# STM32H523 register map
File version: 1.3
CPU: CM33 r0p0, little endian, MPU, FPU, 4 interrupt priority bits
Registers are 32-bit, read-write, reset 0x0 unless marked. A register's access mark holds for its fields unless they carry their own. Offsets are from the block's base; [hi:lo] are bit positions; {n}, {i} and the like mark numbered series; 'fields as' and 'values as' point back to an identical list.

## RCC — RCC address block description
Base 0x44020C00
Same registers: RCC_S 0x54020C00
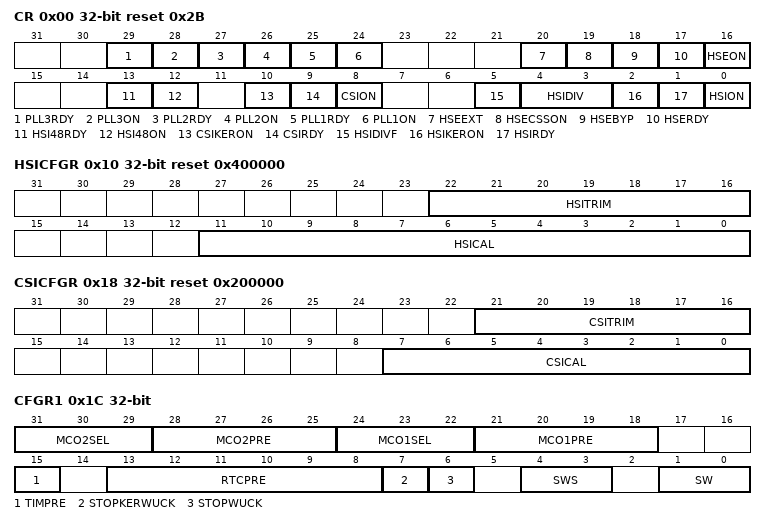
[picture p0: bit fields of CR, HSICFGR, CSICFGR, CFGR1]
0x00 CR reset 0x2B — RCC clock control register
  [29] PLL3RDY ro — PLL3 clock ready flag
    0=NotReady (Clock not ready); 1=Ready (Clock ready)
  [28] PLL3ON — PLL3 enable
    0=Off (Clock Off); 1=On (Clock On)
  [27] PLL2RDY ro — PLL2 clock ready flag
    0=NotReady (Clock not ready); 1=Ready (Clock ready)
  [26] PLL2ON — PLL2 enable
    0=Off (Clock Off); 1=On (Clock On)
  [25] PLL1RDY ro — PLL1 clock ready flag
    0=NotReady (Clock not ready); 1=Ready (Clock ready)
  [24] PLL1ON — PLL1 enable
    0=Off (Clock Off); 1=On (Clock On)
  [20] HSEEXT — external high speed clock type in Bypass mode
    0=Analog (HSE in analog mode); 1=Digital (HSE in digital mode)
  [19] HSECSSON — HSE clock security system enable
    0=Off (Clock Off); 1=On (Clock On)
  [18] HSEBYP — HSE clock bypass
    0=NotBypassed (HSE crystal oscillator not bypassed); 1=Bypassed (HSE crystal oscillator bypassed with external clock)
  [17] HSERDY ro — HSE clock ready flag
    0=NotReady (Clock not ready); 1=Ready (Clock ready)
  [16] HSEON — HSE clock enable
    0=Off (Clock Off); 1=On (Clock On)
  [13] HSI48RDY ro — HSI48 clock ready flag
    0=NotReady (Clock not ready); 1=Ready (Clock ready)
  [12] HSI48ON — HSI48 clock enable
    0=Off (Clock Off); 1=On (Clock On)
  [10] CSIKERON — CSI clock enable in Stop mode
    0=Off (Clock Off); 1=On (Clock On)
  [9] CSIRDY ro — CSI clock ready flag
    0=NotReady (Clock not ready); 1=Ready (Clock ready)
  [8] CSION — CSI clock enable
    0=Off (Clock Off); 1=On (Clock On)
  [5] HSIDIVF ro — HSI divider flag
    0=NotPropagated (New HSIDIV ratio has not yet propagated to hsi_ck); 1=Propagated (HSIDIV ratio has propagated to hsi_ck)
  [4:3] HSIDIV — HSI clock divider
    0=Div1 (No division); 1=Div2 (Division by 2); 2=Div4 (Division by 4); 3=Div8 (Division by 8)
  [2] HSIKERON — HSI clock enable in Stop mode
    0=Off (Clock Off); 1=On (Clock On)
  [1] HSIRDY ro — HSI clock ready flag
    0=NotReady (Clock not ready); 1=Ready (Clock ready)
  [0] HSION — HSI clock enable
    0=Off (Clock Off); 1=On (Clock On)
0x10 HSICFGR reset 0x400000 (reset mask 0xFFFFF000) — RCC HSI calibration register
  [22:16] HSITRIM — HSI clock trimming
  [11:0] HSICAL ro — HSI clock calibration
0x14 CRRCR ro (reset mask 0xFFFFF000) — RCC clock recovery RC register
  [9:0] HSI48CAL — Internal RC 48 MHz clock calibration
0x18 CSICFGR reset 0x200000 (reset mask 0xFFFFF000) — RCC CSI calibration register
  [21:16] CSITRIM — CSI clock trimming
  [7:0] CSICAL — CSI clock calibration
0x1C CFGR1 — RCC clock configuration register1
  [31:29] MCO2SEL — microcontroller clock output 2
    0=SYSCLK (System clock selected (sys_ck)); 1=PLL2_P (PLL2 oscillator clock selected (pll2_p_ck)); 2=HSE (HSE clock selected (hse_ck)); 3=PLL1_P (PLL1 clock selected (pll1_p_ck)); 4=CSI (CSI clock selected (csi_ck)); 5=LSI (LSI clock selected (lsi_ck))
  [28:25] MCO2PRE — MCO2 prescaler
  [24:22] MCO1SEL — Microcontroller clock output 1
    0=HSI (HSI clock selected (hsi_ck)); 1=LSE (LSE clock selected (lse_ck)); 2=HSE (HSE clock selected (hse_ck)); 3=PLL1_Q (PLL1 clock selected (pll1_q_ck)); 4=HSI48 (HSI48 clock selected (hsi48_ck))
  [21:18] MCO1PRE — MCO1 prescaler
  [15] TIMPRE — timers clocks prescaler selection
    0=DefaultX2 (Timer kernel clock equal to 2x pclk by default); 1=DefaultX4 (Timer kernel clock equal to 4x pclk by default)
  [13:8] RTCPRE — HSE division factor for RTC clock
  [7] STOPKERWUCK — kernel clock selection after a wakeup from system Stop
    0=HSI (HSI selected as wake up clock from system Stop); 1=CSI (CSI selected as wake up clock from system Stop)
  [6] STOPWUCK — system clock selection after a wakeup from system Stop
    values as STOPKERWUCK
  [4:3] SWS ro — system clock switch status
    0=HSI (HSI oscillator used as system clock); 1=CSI (CSI oscillator used as system clock); 2=HSE (HSE oscillator used as system clock); 3=PLL1 (PLL1 used as system clock)
  [1:0] SW — system clock and trace clock switch
    0=HSI (HSI selected as system clock); 1=CSI (CSI selected as system clock); 2=HSE (HSE selected as system clock); 3=PLL1 (PLL1 selected as system clock)
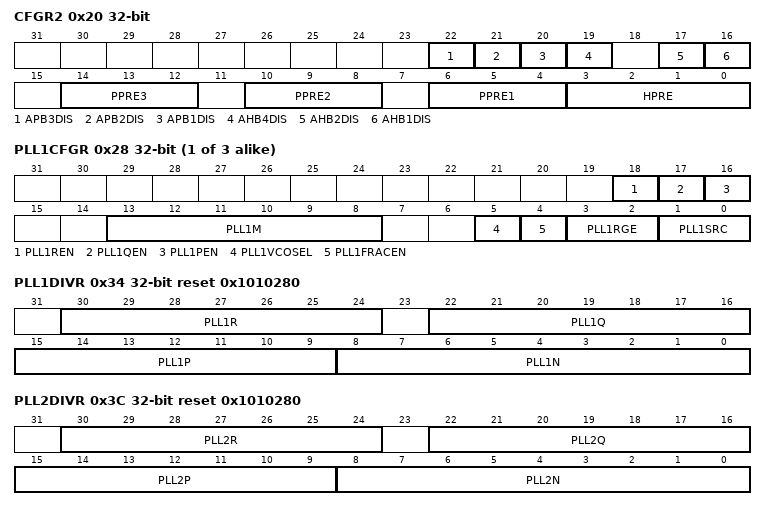
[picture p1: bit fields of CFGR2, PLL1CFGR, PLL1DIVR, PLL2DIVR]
0x20 CFGR2 — RCC CPU domain clock configuration register 2
  [22] APB3DIS — APB3 clock disable value.
    0=Enabled (The selected clock is enabled); 1=Disabled (The selected clock is disabled)
  [21] APB2DIS — APB2 clock disable value
    values as APB3DIS
  [20] APB1DIS — APB1 clock disable value
    values as APB3DIS
  [19] AHB4DIS — AHB4 clock disable
    values as APB3DIS
  [17] AHB2DIS — AHB2 clock disable
    values as APB3DIS
  [16] AHB1DIS — AHB1 clock disable
    values as APB3DIS
  [14:12] PPRE3 — APB low-speed prescaler (APB3)
    4=Div2 (HCLK divided by 2); 5=Div4 (HCLK divided by 4); 6=Div8 (HCLK divided by 8); 7=Div16 (HCLK divided by 16); other=Div1 (HCLK not divided)
  [10:8] PPRE2 — APB high-speed prescaler (APB2)
    values as PPRE3
  [6:4] PPRE1 — APB low-speed prescaler (APB1)
    values as PPRE3
  [3:0] HPRE — AHB prescaler
    8=Div2 (SYSCLK divided by 2); 9=Div4 (SYSCLK divided by 4); 10=Div8 (SYSCLK divided by 8); 11=Div16 (SYSCLK divided by 16); 12=Div64 (SYSCLK divided by 64); 13=Div128 (SYSCLK divided by 128); 14=Div256 (SYSCLK divided by 256); 15=Div512 (SYSCLK divided by 512); other=Div1 (SYSCLK not divided)
{0x24+4i} PLL{i}CFGR (i=1..3) — RCC PLL clock source selection register
  [18] PLL{i}REN — PLL{i} DIVR divider output enable
    0=Disabled (Clock output is disabled); 1=Enabled (Clock output is enabled)
  [17] PLL{i}QEN — PLL{i} DIVQ divider output enable
    values as PLL{i}REN
  [16] PLL{i}PEN — PLL{i} DIVP divider output enable
    values as PLL{i}REN
  [13:8] PLL{i}M — prescaler for PLL{i}
  [5] PLL{i}VCOSEL — PLL{i} VCO selection
    0=WideVCO (VCO frequency range 192 to 836 MHz); 1=MediumVCO (VCO frequency range 150 to 420 MHz)
  [4] PLL{i}FRACEN — PLL{i} fractional latch enable
    0=Reset latch to transfer FRACN to the Sigma-Delta modulator; 1=Set (Set latch to transfer FRACN to the Sigma-Delta modulator)
  [3:2] PLL{i}RGE — PLL{i} input frequency range
    0=Range1 (Frequency is between 1 and 2 MHz); 1=Range2 (Frequency is between 2 and 4 MHz); 2=Range4 (Frequency is between 4 and 8 MHz); 3=Range8 (Frequency is between 8 and 16 MHz)
  [1:0] PLL{i}SRC — PLL{i}M and PLLs clock source selection
    0=None (No clock sent to DIVMx dividers and PLLs); 1=HSI (HSI selected as PLL clock); 2=CSI (CSI selected as PLL clock); 3=HSE (HSE selected as PLL clock)
0x34 PLL1DIVR reset 0x1010280 — RCC PLL1 dividers register
  [30:24] PLL1R — PLL1 DIVR division factor
  [22:16] PLL1Q — PLL1 DIVQ division factor
  [15:9] PLL1P — PLL1 DIVP division factor
  [8:0] PLL1N range 3..511 — Multiplication factor for PLL1VCO
{0x30+8i} PLL{i}FRACR (i=1..3) — RCC PLL{i} fractional divider register
  [15:3] PLL{i}FRACN — fractional part of the multiplication factor for PLL{i} VCO
0x3C PLL2DIVR reset 0x1010280 — RCC PLL1 dividers register
  [30:24] PLL2R — PLL2 DIVR division factor
  [22:16] PLL2Q — PLL2 DIVQ division factor
  [15:9] PLL2P — PLL2 DIVP division factor
  [8:0] PLL2N range 3..511 — Multiplication factor for PLL2VCO
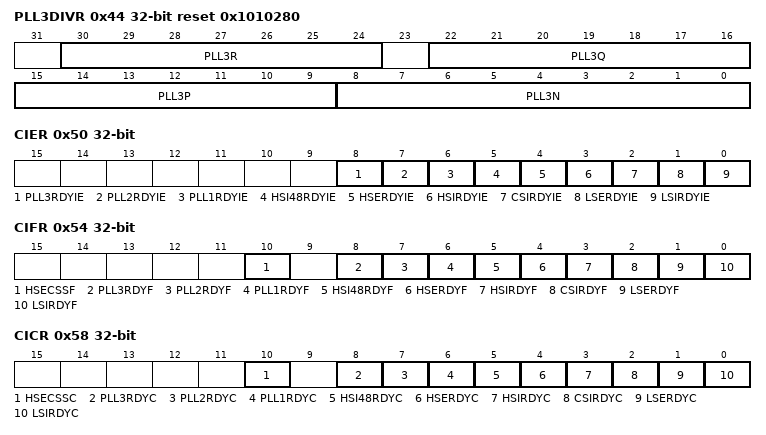
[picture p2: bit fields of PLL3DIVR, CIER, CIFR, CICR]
0x44 PLL3DIVR reset 0x1010280 — RCC PLL3 dividers register
  [30:24] PLL3R — PLL3 DIVR division factor
  [22:16] PLL3Q — PLL3 DIVQ division factor
  [15:9] PLL3P — PLL3 DIVP division factor
  [8:0] PLL3N range 3..511 — Multiplication factor for PLL3VCO
0x50 CIER — RCC clock source interrupt enable register
  [all] fields
    0=Disabled (Interrupt disabled); 1=Enabled (Interrupt enabled)
  [8] PLL3RDYIE — PLL3 ready interrupt enable
  [7] PLL2RDYIE — PLL2 ready interrupt enable
  [6] PLL1RDYIE — PLL1 ready interrupt enable
  [5] HSI48RDYIE — HSI48 ready interrupt enable
  [4] HSERDYIE — HSE ready interrupt enable
  [3] HSIRDYIE — HSI ready interrupt enable
  [2] CSIRDYIE — CSI ready interrupt enable
  [1] LSERDYIE — LSE ready interrupt enable
  [0] LSIRDYIE — LSI ready interrupt enable
0x54 CIFR ro — RCC clock source interrupt flag register
  [10] HSECSSF — HSE clock security system interrupt flag
    0=NoInterrupt (No clock security interrupt caused by HSE clock failure); 1=Interrupt (Clock security interrupt caused by HSE clock failure)
  [8] PLL3RDYF — PLL3 ready interrupt flag
    0=NotInterrupted (No clock ready interrupt); 1=Interrupted (Clock ready interrupt)
  [7] PLL2RDYF — PLL2 ready interrupt flag
    values as PLL3RDYF
  [6] PLL1RDYF — PLL1 ready interrupt flag
    values as PLL3RDYF
  [5] HSI48RDYF — HSI48 ready interrupt flag
    values as PLL3RDYF
  [4] HSERDYF — HSE ready interrupt flag
    values as PLL3RDYF
  [3] HSIRDYF — HSI ready interrupt flag
    values as PLL3RDYF
  [2] CSIRDYF — CSI ready interrupt flag
    values as PLL3RDYF
  [1] LSERDYF — LSE ready interrupt flag
    values as PLL3RDYF
  [0] LSIRDYF — LSI ready interrupt flag
    values as PLL3RDYF
0x58 CICR — RCC clock source interrupt clear register
  [all] fields
    1=Clear interrupt flag
  [10] HSECSSC — HSE clock security system interrupt clear
  [8] PLL3RDYC — PLL3 ready interrupt clear
  [7] PLL2RDYC — PLL2 ready interrupt clear
  [6] PLL1RDYC — PLL1 ready interrupt clear
  [5] HSI48RDYC — HSI48 ready interrupt clear
  [4] HSERDYC — HSE ready interrupt clear
  [3] HSIRDYC — HSI ready interrupt clear
  [2] CSIRDYC — HSI ready interrupt clear
  [1] LSERDYC — LSE ready interrupt clear
  [0] LSIRDYC — LSI ready interrupt clear
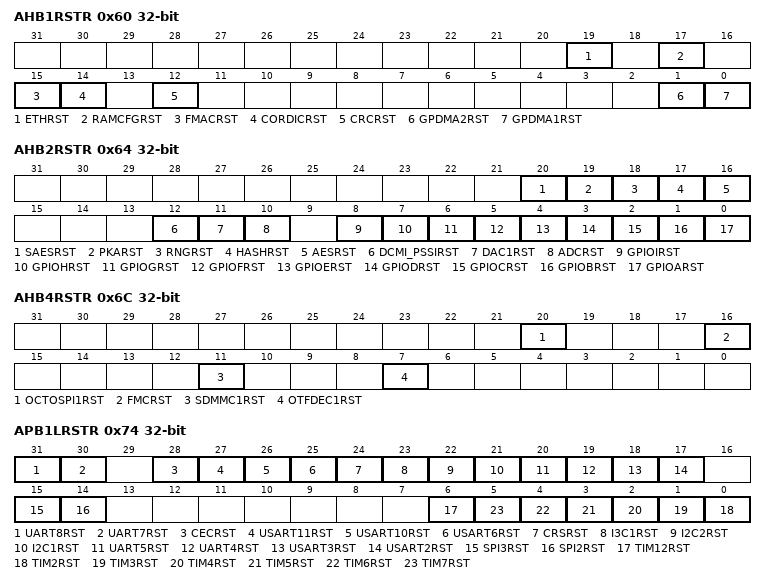
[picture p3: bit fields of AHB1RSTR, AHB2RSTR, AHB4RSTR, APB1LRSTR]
0x60 AHB1RSTR — RCC AHB1 reset register
  [all] fields
    1=Reset the selected module
  [19] ETHRST — ETHRST block reset
  [17] RAMCFGRST — RAMCFG block reset
  [15] FMACRST — FMAC block reset
  [14] CORDICRST — CORDIC block reset
  [12] CRCRST — CRC block reset Set and reset by software.
  [1] GPDMA2RST — GPDMA2 block reset
  [0] GPDMA1RST — GPDMA1 block reset
0x64 AHB2RSTR — RCC AHB2 peripheral reset register
  [all] fields
    1=Reset the selected module
  [20] SAESRST — SAES block reset
  [19] PKARST — PKA block reset
  [18] RNGRST — RNG block reset
  [17] HASHRST — HASH block reset
  [16] AESRST — AES block reset
  [12] DCMI_PSSIRST — digital camera interface block reset (DCMI or PSSI depending which interface is active)
  [11] DAC1RST — DAC block reset
  [10] ADCRST — ADC1 and 2 blocks reset
  [8] GPIOIRST — GPIOI block reset
  [7] GPIOHRST — GPIOH block reset
  [6] GPIOGRST — GPIOG block reset
  [5] GPIOFRST — GPIOF block reset
  [4] GPIOERST — GPIOE block reset
  [3] GPIODRST — GPIOD block reset
  [2] GPIOCRST — GPIOC block reset
  [1] GPIOBRST — GPIOB block reset
  [0] GPIOARST — GPIOA block reset
0x6C AHB4RSTR — RCC AHB4 peripheral reset register
  [all] fields
    1=Reset the selected module
  [20] OCTOSPI1RST — OCTOSPI1 block reset
  [16] FMCRST — FMC block reset
  [11] SDMMC1RST — SDMMC1 and SDMMC1 delay blocks reset
  [7] OTFDEC1RST — OTFDEC1 block reset
0x74 APB1LRSTR — RCC APB1 peripheral low reset register
  [all] fields
    1=Reset the selected module
  [31] UART8RST — UART8 block reset
  [30] UART7RST — UART7 block reset
  [28] CECRST — HDMI-CEC block reset
  [27] USART11RST — USART11 block reset
  [26] USART10RST — USART10 block reset
  [25] USART6RST — USART6 block reset
  [24] CRSRST — CRS block reset
  [23] I3C1RST — I3C1 block reset
  [22] I2C2RST — I2C2 block reset
  [21] I2C1RST — I2C1 block reset
  [20] UART5RST — UART5 block reset
  [19] UART4RST — UART4 block reset
  [18] USART3RST — USART3 block reset
  [17] USART2RST — USART2 block reset
  [15] SPI3RST — SPI3 block reset
  [14] SPI2RST — SPI2 block reset
  [6] TIM12RST — TIM12 block reset
  [n-2] TIM{n}RST (n=2..7) — TIM{n} block reset
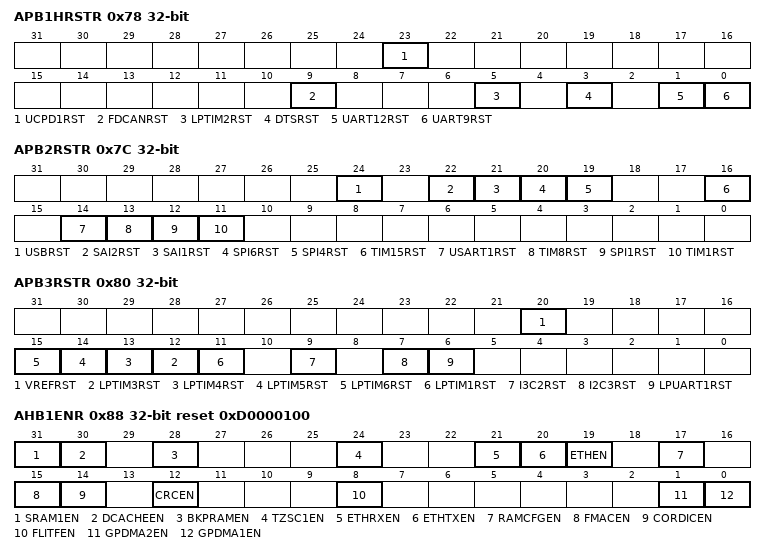
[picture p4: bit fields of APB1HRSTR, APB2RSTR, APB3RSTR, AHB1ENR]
0x78 APB1HRSTR — RCC APB1 peripheral high reset register
  [all] fields
    1=Reset the selected module
  [23] UCPD1RST — UCPD1 block reset
  [9] FDCANRST — FDCAN1 and FDCAN2 blocks reset
  [5] LPTIM2RST — LPTIM2 block reset
  [3] DTSRST — DTS block reset
  [1] UART12RST — UART12 block reset
  [0] UART9RST — UART9 block reset
0x7C APB2RSTR — RCC APB2 peripheral reset register
  [all] fields
    1=Reset the selected module
  [24] USBRST — USB block reset
  [22] SAI2RST — SAI2 block reset
  [21] SAI1RST — SAI1 block reset
  [20] SPI6RST — SPI6 block reset
  [19] SPI4RST — SPI4 block reset
  [16] TIM15RST — TIM15 block reset
  [14] USART1RST — USART1 block reset
  [13] TIM8RST — TIM8 block reset
  [12] SPI1RST — SPI1 block reset
  [11] TIM1RST — TIM1 block reset
0x80 APB3RSTR — RCC APB3 peripheral reset register
  [all] fields
    1=Reset the selected module
  [20] VREFRST — VREFBUF block reset
  [n+9] LPTIM{n}RST (n=3..6) — LPTIM{n} block reset
  [11] LPTIM1RST — LPTIM1 block reset
  [9] I3C2RST — I3C2 block reset
  [7] I2C3RST — I2C3 block reset
  [6] LPUART1RST — LPUART1 block reset
0x88 AHB1ENR reset 0xD0000100 — RCC AHB1 peripherals clock register
  [all] fields
    0=Disabled (The selected clock is disabled); 1=Enabled (The selected clock is enabled)
  [31] SRAM1EN — SRAM1 clock enable
  [30] DCACHEEN — DCACHE clock enable
  [28] BKPRAMEN — BKPRAM clock enable
  [24] TZSC1EN — TZSC1 clock enable
  [21] ETHRXEN — ETHRX clock enable
  [20] ETHTXEN — ETHTX clock enable
  [19] ETHEN — ETH clock enable
  [17] RAMCFGEN — RAMCFG clock enable
  [15] FMACEN — FMAC clock enable
  [14] CORDICEN — CORDIC clock enable
  [12] CRCEN — CRC clock enable
  [8] FLITFEN — Flash interface clock enable
  [1] GPDMA2EN — GPDMA2 clock enable
  [0] GPDMA1EN — GPDMA1 clock enable
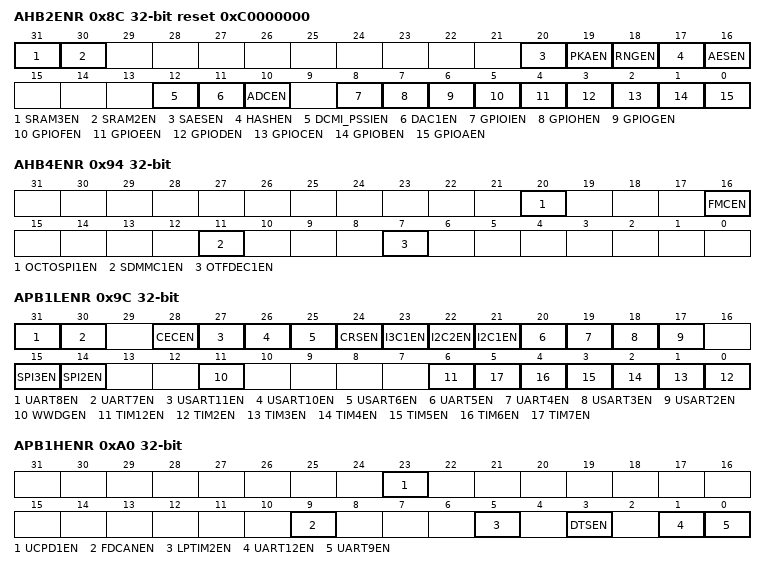
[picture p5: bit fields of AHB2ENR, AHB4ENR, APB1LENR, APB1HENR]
0x8C AHB2ENR reset 0xC0000000 — RCC AHB2 peripheral clock register
  [all] fields
    values as the fields of AHB1ENR
  [31] SRAM3EN — SRAM3 clock enable
  [30] SRAM2EN — SRAM2 clock enable
  [20] SAESEN — SAES clock enable
  [19] PKAEN — PKA clock enable
  [18] RNGEN — RNG clock enable
  [17] HASHEN — HASH clock enable
  [16] AESEN — AES clock enable
  [12] DCMI_PSSIEN — digital camera interface clock enable (DCMI or PSSI depending which interface is active)
  [11] DAC1EN — DAC clock enable
  [10] ADCEN — ADC1 and 2 peripherals clock enable
  [8] GPIOIEN — GPIOI clock enable
  [7] GPIOHEN — GPIOH clock enable
  [6] GPIOGEN — GPIOG clock enable
  [5] GPIOFEN — GPIOF clock enable
  [4] GPIOEEN — GPIOE clock enable
  [3] GPIODEN — GPIOD clock enable
  [2] GPIOCEN — GPIOC clock enable
  [1] GPIOBEN — GPIOB clock enable
  [0] GPIOAEN — GPIOA clock enable
0x94 AHB4ENR — RCC AHB4 peripheral clock register
  [all] fields
    values as the fields of AHB1ENR
  [20] OCTOSPI1EN — OCTOSPI1 clock enable
  [16] FMCEN — FMC clock enable
  [11] SDMMC1EN — SDMMC1 and SDMMC1 delay peripheral clock enable reset
  [7] OTFDEC1EN — OTFDEC1 clock enable
0x9C APB1LENR — RCC APB1 peripheral clock register
  [all] fields
    values as the fields of AHB1ENR
  [31] UART8EN — UART8 clock enable
  [30] UART7EN — UART7 clock enable
  [28] CECEN — HDMI-CEC clock enable
  [27] USART11EN — USART11 clock enable
  [26] USART10EN — USART10 clock enable
  [25] USART6EN — USART6 clock enable
  [24] CRSEN — CRS clock enable
  [23] I3C1EN — I3C1 clock enable
  [22] I2C2EN — I2C2 clock enable
  [21] I2C1EN — I2C1 clock enable
  [20] UART5EN — UART5 clock enable
  [19] UART4EN — UART4 clock enable
  [18] USART3EN — USART3 clock enable
  [17] USART2EN — USART2 clock enable
  [15] SPI3EN — SPI3 clock enable
  [14] SPI2EN — SPI2 clock enable
  [11] WWDGEN — WWDG clock enable
  [6] TIM12EN — TIM12 clock enable
  [n-2] TIM{n}EN (n=2..7) — TIM{n} clock enable
0xA0 APB1HENR — RCC APB1 peripheral clock register
  [all] fields
    values as the fields of AHB1ENR
  [23] UCPD1EN — UCPD1 clock enable
  [9] FDCANEN — FDCAN1 and FDCAN2 peripheral clock enable
  [5] LPTIM2EN — LPTIM2 clock enable
  [3] DTSEN — DTS clock enable
  [1] UART12EN — UART12 clock enable
  [0] UART9EN — UART9 clock enable
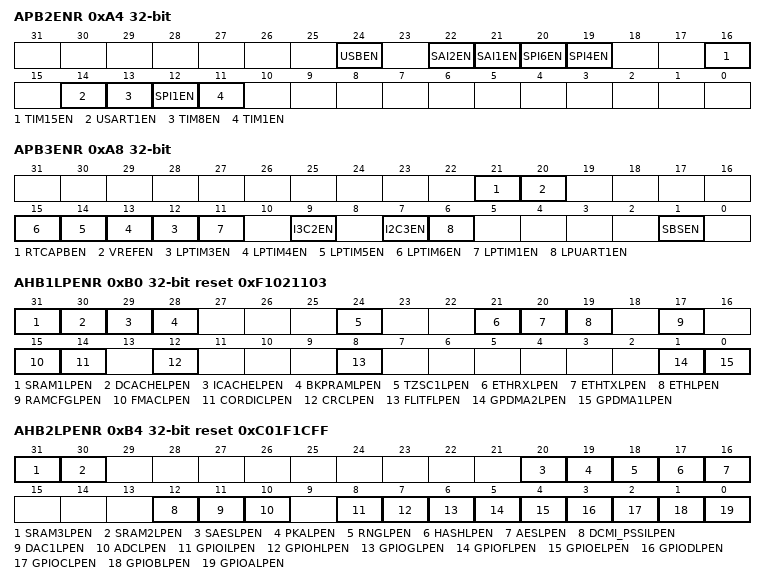
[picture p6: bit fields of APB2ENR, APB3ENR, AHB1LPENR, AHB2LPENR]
0xA4 APB2ENR — RCC APB2 peripheral clock register
  [all] fields
    values as the fields of AHB1ENR
  [24] USBEN — USB clock enable
  [22] SAI2EN — SAI2 clock enable
  [21] SAI1EN — SAI1 clock enable
  [20] SPI6EN — SPI6 clock enable
  [19] SPI4EN — SPI4 clock enable
  [16] TIM15EN — TIM15 clock enable
  [14] USART1EN — USART1 clock enable
  [13] TIM8EN — TIM8 clock enable
  [12] SPI1EN — SPI1 clock enable
  [11] TIM1EN — TIM1 clock enable
0xA8 APB3ENR — RCC APB3 peripheral clock register
  [all] fields
    values as the fields of AHB1ENR
  [21] RTCAPBEN — RTC APB interface clock enable
  [20] VREFEN — VREFBUF clock enable
  [n+9] LPTIM{n}EN (n=3..6) — LPTIM{n} clock enable
  [11] LPTIM1EN — LPTIM1 clock enable
  [9] I3C2EN — I3C2 clock enable
  [7] I2C3EN — I2C3 clock enable
  [6] LPUART1EN — LPUART1 clock enable
  [1] SBSEN — SBS clock enable
0xB0 AHB1LPENR reset 0xF1021103 — RCC AHB1 sleep clock register
  [all] fields
    0=Disabled (The selected clock is disabled during csleep mode); 1=Enabled (The selected clock is enabled during csleep mode)
  [31] SRAM1LPEN — SRAM1 clock enable during Sleep mode
  [30] DCACHELPEN — DCACHE clock enable during Sleep mode
  [29] ICACHELPEN — ICACHE clock enable during Sleep mode
  [28] BKPRAMLPEN — BKPRAM clock enable during Sleep mode
  [24] TZSC1LPEN — TZSC1 clock enable during Sleep mode
  [21] ETHRXLPEN — ETHRX clock enable during Sleep mode
  [20] ETHTXLPEN — ETHTX clock enable during Sleep mode
  [19] ETHLPEN — ETH clock enable during Sleep mode
  [17] RAMCFGLPEN — RAMCFG clock enable during Sleep mode
  [15] FMACLPEN — FMAC clock enable during Sleep mode
  [14] CORDICLPEN — CORDIC clock enable during Sleep mode
  [12] CRCLPEN — CRC clock enable during Sleep mode
  [8] FLITFLPEN — Flash interface (FLITF) clock enable during Sleep mode
  [1] GPDMA2LPEN — GPDMA2 clock enable during Sleep mode
  [0] GPDMA1LPEN — GPDMA1 clock enable during Sleep mode
0xB4 AHB2LPENR reset 0xC01F1CFF — RCC AHB2 sleep clock register
  [all] fields
    values as the fields of AHB1LPENR
  [31] SRAM3LPEN — SRAM3 clock enable during Sleep mode
  [30] SRAM2LPEN — SRAM2 clock enable during Sleep mode
  [20] SAESLPEN — SAES clock enable during Sleep mode
  [19] PKALPEN — PKA clock enable during Sleep mode
  [18] RNGLPEN — RNG clock enable during Sleep mode
  [17] HASHLPEN — HASH clock enable during Sleep mode
  [16] AESLPEN — AES clock enable during Sleep mode
  [12] DCMI_PSSILPEN — digital camera interface clock enable during Sleep mode (DCMI or PSSI depending which interface is active)
  [11] DAC1LPEN — DAC clock enable during Sleep mode
  [10] ADCLPEN — ADC1 and 2 peripherals clock enable during Sleep mode
  [8] GPIOILPEN — GPIOI clock enable during Sleep mode
  [7] GPIOHLPEN — GPIOH clock enable during Sleep mode
  [6] GPIOGLPEN — GPIOG clock enable during Sleep mode
  [5] GPIOFLPEN — GPIOF clock enable during Sleep mode
  [4] GPIOELPEN — GPIOE clock enable during Sleep mode
  [3] GPIODLPEN — GPIOD clock enable during Sleep mode
  [2] GPIOCLPEN — GPIOC clock enable during Sleep mode
  [1] GPIOBLPEN — GPIOB clock enable during Sleep mode
  [0] GPIOALPEN — GPIOA clock enable during Sleep mode
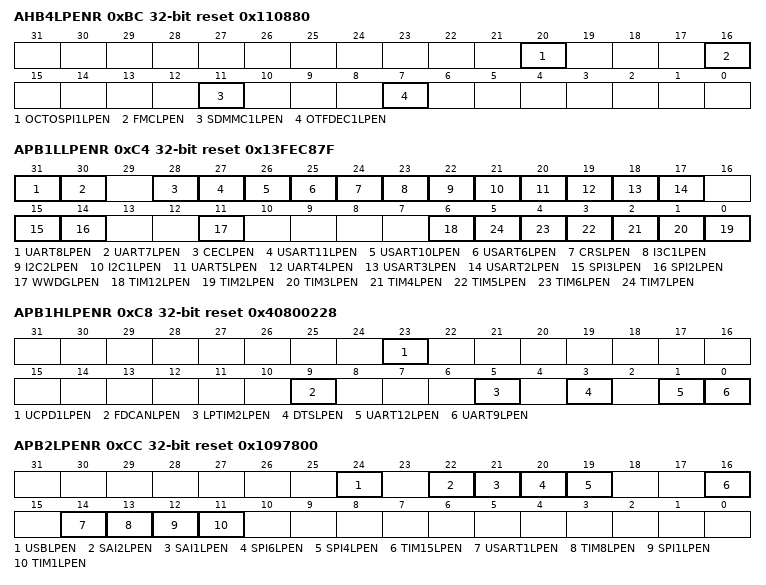
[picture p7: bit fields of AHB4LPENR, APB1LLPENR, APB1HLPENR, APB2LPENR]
0xBC AHB4LPENR reset 0x110880 — RCC AHB4 sleep clock register
  [all] fields
    values as the fields of AHB1LPENR
  [20] OCTOSPI1LPEN — OCTOSPI1 clock enable during Sleep mode
  [16] FMCLPEN — FMC clock enable during Sleep mode
  [11] SDMMC1LPEN — SDMMC1 and SDMMC1 delay peripheral clock enable during Sleep mode
  [7] OTFDEC1LPEN — OTFDEC1 clock enable during Sleep mode
0xC4 APB1LLPENR reset 0x13FEC87F — RCC APB1 sleep clock register
  [all] fields
    values as the fields of AHB1LPENR
  [31] UART8LPEN — UART8 clock enable during Sleep mode
  [30] UART7LPEN — UART7 clock enable during Sleep mode
  [28] CECLPEN — HDMI-CEC clock enable during Sleep mode
  [27] USART11LPEN — USART11 clock enable during Sleep mode
  [26] USART10LPEN — USART10 clock enable during Sleep mode
  [25] USART6LPEN — USART6 clock enable during Sleep mode
  [24] CRSLPEN — CRS clock enable during Sleep mode
  [23] I3C1LPEN — I3C1 clock enable during Sleep mode
  [22] I2C2LPEN — I2C2 clock enable during Sleep mode
  [21] I2C1LPEN — I2C1 clock enable during Sleep mode
  [20] UART5LPEN — UART5 clock enable during Sleep mode
  [19] UART4LPEN — UART4 clock enable during Sleep mode
  [18] USART3LPEN — USART3 clock enable during Sleep mode
  [17] USART2LPEN — USART2 clock enable during Sleep mode
  [15] SPI3LPEN — SPI3 clock enable during Sleep mode
  [14] SPI2LPEN — SPI2 clock enable during Sleep mode
  [11] WWDGLPEN — WWDG clock enable during Sleep mode
  [6] TIM12LPEN — TIM12 clock enable during Sleep mode
  [n-2] TIM{n}LPEN (n=2..7) — TIM{n} clock enable during Sleep mode
0xC8 APB1HLPENR reset 0x40800228 — RCC APB1 sleep clock register
  [all] fields
    values as the fields of AHB1LPENR
  [23] UCPD1LPEN — UCPD1 clock enable during Sleep mode
  [9] FDCANLPEN — FDCAN1 and FDCAN2 peripheral clock enable during Sleep mode
  [5] LPTIM2LPEN — LPTIM2 clock enable during Sleep mode
  [3] DTSLPEN — DTS clock enable during Sleep mode
  [1] UART12LPEN — UART12 clock enable during Sleep mode
  [0] UART9LPEN — UART9 clock enable during Sleep mode
0xCC APB2LPENR reset 0x1097800 — RCC APB2 sleep clock register
  [all] fields
    values as the fields of AHB1LPENR
  [24] USBLPEN — USB clock enable during Sleep mode
  [22] SAI2LPEN — SAI2 clock enable during Sleep mode
  [21] SAI1LPEN — SAI1 clock enable during Sleep mode
  [20] SPI6LPEN — SPI6 clock enable during Sleep mode
  [19] SPI4LPEN — SPI4 clock enable during Sleep mode
  [16] TIM15LPEN — TIM15 clock enable during Sleep mode
  [14] USART1LPEN — USART1 clock enable during Sleep mode
  [13] TIM8LPEN — TIM8 clock enable during Sleep mode
  [12] SPI1LPEN — SPI1 clock enable during Sleep mode
  [11] TIM1LPEN — TIM1 clock enable during Sleep mode
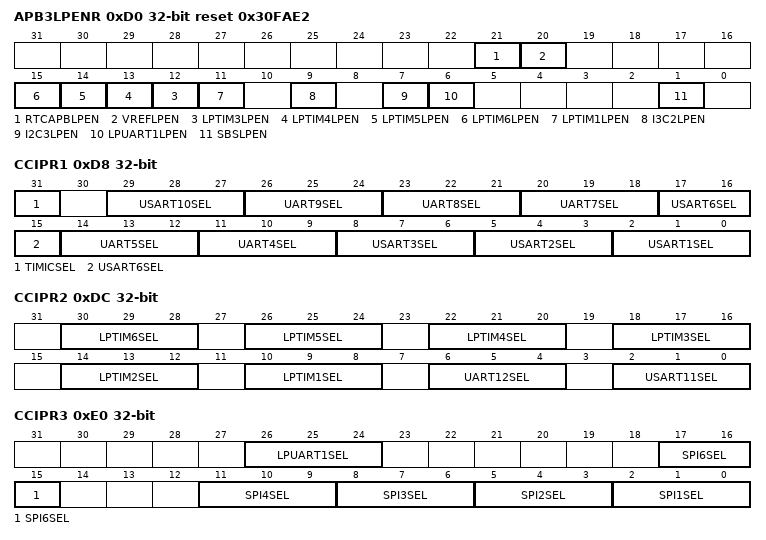
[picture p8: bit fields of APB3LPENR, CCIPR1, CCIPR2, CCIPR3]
0xD0 APB3LPENR reset 0x30FAE2 — RCC APB3 sleep clock register
  [all] fields
    values as the fields of AHB1LPENR
  [21] RTCAPBLPEN — RTC APB interface clock enable during Sleep mode
  [20] VREFLPEN — VREFBUF clock enable during Sleep mode
  [n+9] LPTIM{n}LPEN (n=3..6) — LPTIM{n} clock enable during Sleep mode
  [11] LPTIM1LPEN — LPTIM1 clock enable during Sleep mode
  [9] I3C2LPEN — I3C2 clock enable during Sleep mode
  [7] I2C3LPEN — I2C3 clock enable during Sleep mode
  [6] LPUART1LPEN — LPUART1 clock enable during Sleep mode
  [1] SBSLPEN — SBS clock enable during Sleep mode
0xD8 CCIPR1 — RCC kernel clock configuration register
  [31] TIMICSEL — TIM12, TIM15 and LPTIM2 input capture source selection
    0=Disabled (No internal clock available for timers input capture); 1=Enabled (hsi_ker_ck/1024, hsi_ker_ck/8 and csi_ker_ck/128 selected for timers input capture)
  [29:27] USART10SEL — USART10 kernel clock source selection
    0=PCLK (Peripheral bus clock used as selected as clock source (rcc_pclk_x)); 1=PLL2_Q (PLL2 Q clock selected as clock source (pll2_q_ck)); 2=PLL3_Q (PLL3 Q clock selected as clock source (pll3_q_ck)); 3=HSI_KER (HSI kernel clock selected as clock source (hsi_ker_ck)); 4=CSI_KER (CSI kernel clock selected as clock source (csi_ker_ck)); 5=LSE (LSE clock selected as clock source (lse_ck))
  [26:24] UART9SEL — UART9 kernel clock source selection
    values as USART10SEL
  [23:21] UART8SEL — UART8 kernel clock source selection
    values as USART10SEL
  [20:18] UART7SEL — UART7 kernel clock source selection
    values as USART10SEL
  [17:15] USART6SEL — USART6 kernel clock source selection
    values as USART10SEL
  [14:12] UART5SEL — UART5 kernel clock source selection
    values as USART10SEL
  [11:9] UART4SEL — UART4 kernel clock source selection
    values as USART10SEL
  [8:6] USART3SEL — USART3 kernel clock source selection
    values as USART10SEL
  [5:3] USART2SEL — USART2 kernel clock source selection
    values as USART10SEL
  [2:0] USART1SEL — USART1 kernel clock source selection
    values as USART10SEL
0xDC CCIPR2 — RCC kernel clock configuration register
  [4n+6:4n+4] LPTIM{n}SEL (n=1..6) — LPTIM{n} kernel clock source selection
    0=PCLK (Peripheral bus clock used as selected as clock source (rcc_pclk_x)); 1=PLL2_P (PLL2 P clock selected as clock source (pll2_p_ck)); 2=PLL3_R (PLL3 R clock selected as clock source (pll3_r_ck)); 3=LSE_KER (LSE kernel selected as clock source (lse_ck)); 4=LSI_KER (LSI kernel selected as clock source (lsi_ker_ck)); 5=PER_CK (per_ck clock selected as clock source)
  [6:4] UART12SEL — UART12 kernel clock source selection
    values as CCIPR1.USART10SEL
  [2:0] USART11SEL — USART11 kernel clock source selection
    values as CCIPR1.USART10SEL
0xE0 CCIPR3 — RCC kernel clock configuration register
  [26:24] LPUART1SEL — LPUART1 kernel clock source selection
    values as CCIPR1.USART10SEL
  [17:15] SPI6SEL — SPI6 kernel clock source selection
    0=PCLK (Peripheral bus clock used as selected as clock source (rcc_pclk_x)); 1=PLL2_Q (PLL2 Q clock selected as clock source (pll2_p_ck)); 2=PLL3_Q (PLL3 Q clock selected as clock source (pll3_p_ck)); 3=HSI_KER (HSI kernel clock selected as clock source (hsi_ker_ck)); 4=CSI_KER (CSI kernel clock selected as clock source (csi_ker_ck)); 5=HSE (HSE clock selected as clock source (hse_ck))
  [11:9] SPI4SEL — SPI4 kernel clock source selection
    values as SPI6SEL
  [8:6] SPI3SEL — SPI3 kernel clock source selection
    0=PLL1_Q (PLL1 Q clock selected as clock source (pll1_q_ck)); 1=PLL2_P (PLL2 P clock selected as clock source (pll2_p_ck)); 2=PLL3_P (PLL3 P clock selected as clock source (pll3_p_ck)); 3=AUDIOCLK (AUDIOCLK clock selected as clock source); 4=PER_CK (per_ck clock selected as clock source)
  [5:3] SPI2SEL — SPI2 kernel clock source selection
    values as SPI3SEL
  [2:0] SPI1SEL — SPI1 kernel clock source selection
    values as SPI3SEL
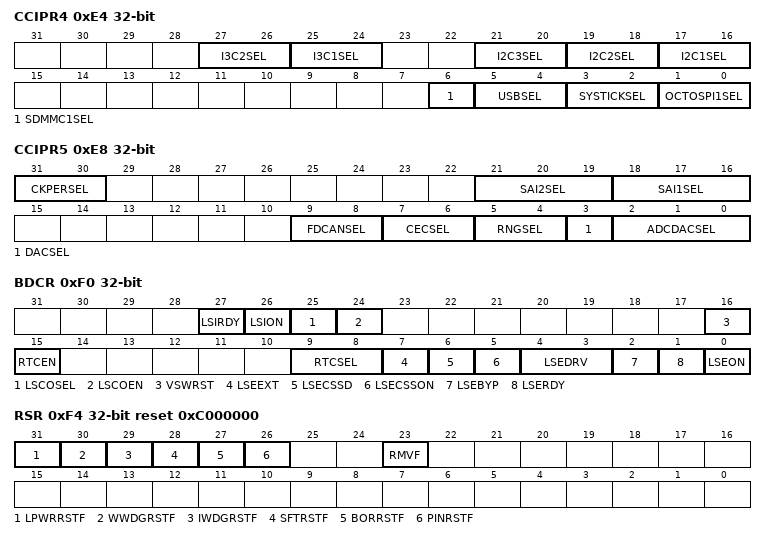
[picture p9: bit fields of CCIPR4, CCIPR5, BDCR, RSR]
0xE4 CCIPR4 — RCC kernel clock configuration register
  [27:26] I3C2SEL — I3C2 kernel clock source selection
    0=PCLK (Peripheral bus clock used as selected as clock source (rcc_pclk_x)); 1=PLL3_R (PLL3 R clock selected as clock source (pll3_r_ck)); 2=HSI_KER (HSI kernel clock selected as clock source (hsi_ker_ck))
  [25:24] I3C1SEL — I3C1 kernel clock source selection
    values as I3C2SEL
  [21:20] I2C3SEL — I2C3 kernel clock source selection
    0=PCLK (Peripheral bus clock used as selected as clock source (rcc_pclk_x)); 1=PLL3_R (PLL3 R Clock selected as clock source (pll3_r_ck)); 2=HSI_KER (HSI kernel clock selected as clock source (hsi_ker_ck)); 3=CSI_KER (CSI kernel clock selected as clock source (csi_ker_ck))
  [19:18] I2C2SEL — I2C2 kernel clock source selection
    values as I2C3SEL
  [17:16] I2C1SEL — I2C1 kernel clock source selection
    values as I2C3SEL
  [6] SDMMC1SEL — SDMMC1 kernel clock source selection
    0=PLL1_Q (PLL1 Q clock selected as clock source (pll1_q_ck)); 1=PLL2_R (PLL2 R clock selected as clock source (pll2_r_ck))
  [5:4] USBSEL — USB kernel clock source selection
    0=DISABLE (Disable the clock); 1=PLL1_Q (PLL1 Q clock selected as clock source (pll1_q_ck)); 2=PLL3_Q (PLL3 Q clock selected as clock source (pll3_q_ck)); 3=HSI48 (HSI48 clock selected as clock source (hsi48_ker_ck))
  [3:2] SYSTICKSEL — SYSTICK clock source selection
    0=HCLK_DIV8 (RCC HLCK divided by 8 selected as clock source (rcc_hclk / 8)); 1=LSI_KER (LSI kernel selected as clock source (lsi_ker_ck)); 2=LSE (LSE selected as clock source (lse_ck))
  [1:0] OCTOSPI1SEL — OCTOSPI1 kernel clock source selection
    0=RCC_HCLK4 (HCLK4 selected as clock source (rcc_hclk4)); 1=PLL1_Q (PLL1 Q clock selected as clock source (pll1_q_ck)); 2=PLL2_R (PLL2 R clock selected as clock source (pll2_r_ck)); 3=PER_CK (per_ck clock selected as clock source)
0xE8 CCIPR5 — RCC kernel clock configuration register
  [31:30] CKPERSEL — per_ck clock source selection
    0=HSI_KER (HSI kernel clock selected as clock source (hsi_ker_ck)); 1=CSI_KER (CSI kernel clock selected as clock source (csi_ker_ck)); 2=HSE (HSE clock selected as clock source (hse_ck))
  [21:19] SAI2SEL — SAI2 kernel clock source selection
    values as CCIPR3.SPI3SEL
  [18:16] SAI1SEL — SAI1 kernel clock source selection
    values as CCIPR3.SPI3SEL
  [9:8] FDCANSEL — FDCAN1 and FDCAN2 kernel clock source selection
    0=HSE (HSE clock selected as clock source (hse_ck)); 1=PLL1_Q (PLL1 Q clock selected as clock source (pll1_q_ck)); 2=PLL2_Q (PLL2 Q clock selected as clock source (pll2_q_ck))
  [7:6] CECSEL — HSMI-CEC kernel clock source selection
    0=LSE (LSE selected as clock source (lse_ck)); 1=LSI_KER (LSI kernel selected as clock source (lsi_ker_ck)); 2=CSI_KER (CSI kernel clock divided by 122 selected as clock source (csi_ker_ck/122))
  [5:4] RNGSEL — RNG kernel clock source selection
    0=HSI48_KER (HSI48 kernel clock selected as clock source (hsi48_ker_ck)); 1=PLL1_Q (PLL1 Q clock selected as clock source (pll1_q_ck)); 2=LSE (LSE clock selected as clock source (lse_ck)); 3=LSI (LSI kernel clock selected as clock source (lsi_ker_ck))
  [3] DACSEL — DAC sample and hold clock
    0=LSE (LSE selected as clock source (lse_ck)); 1=LSI_KER (LSI kernel selected as clock source (lsi_ker_ck))
  [2:0] ADCDACSEL — ADC and DAC kernel clock source selection
    0=HCLK (HLCK clock selected as clock source (rcc_hclk)); 1=SYS (System clock selected as pclock source (sys_ck)); 2=PLL2_R (PLL2 R clock selected as clock source (pll2_r_ck)); 3=HSE (HSE clock selected as clock source (hse_ck)); 4=HSI_KER (HSI kernel clock selected as clock source (hsi_ker_ck)); 5=CSI_KER (CSI kernel clock selected as clock source (csi_ker_ck))
0xF0 BDCR — RCC Backup domain control register
  [27] LSIRDY — LSI oscillator ready
    on read: 0=NotReady (Clock not ready); 1=Ready (Clock ready)
  [26] LSION — LSI oscillator enable
    0=Disabled (Oscillator disabled); 1=Enabled (Oscillator enabled)
  [25] LSCOSEL — Low-speed clock output selection
    0=LSI (LSI clock selected); 1=LSE (LSE clock selected)
  [24] LSCOEN — Low-speed clock output (LSCO) enable
  [16] VSWRST — VSwitch domain software reset
    0=NotActivated (Reset not activated); 1=Resets the entire VSW domain
  [15] RTCEN — RTC clock enable
    0=Disabled (RTC clock disabled); 1=Enabled (RTC clock enabled)
  [9:8] RTCSEL — RTC clock source selection
    0=NoClock; 1=LSE (LSE oscillator clock used as RTC clock); 2=LSI (LSI oscillator clock used as RTC clock); 3=HSE (HSE oscillator clock divided by a prescaler used as RTC clock)
  [7] LSEEXT — low-speed external clock type in bypass mode
    values as CR.HSEEXT
  [6] LSECSSD — LSE clock security system failure detection
    on read: 0=No failure detected on 32 kHz oscillator; 1=Failure detected on 32 kHz oscillator
  [5] LSECSSON — LSE clock security system enable
    0=SecurityOff (Clock security system on 32 kHz oscillator off); 1=SecurityOn (Clock security system on 32 kHz oscillator on)
  [4:3] LSEDRV — LSE oscillator driving capability
    0=Lowest LSE oscillator driving capability; 1=Medium low LSE oscillator driving capability; 2=Medium high LSE oscillator driving capability; 3=Highest LSE oscillator driving capability
  [2] LSEBYP — LSE oscillator bypass
    0=NotBypassed (LSE crystal oscillator not bypassed); 1=Bypassed (LSE crystal oscillator bypassed with external clock)
  [1] LSERDY — LSE oscillator ready
    on read: 0=NotReady (LSE oscillator not ready); 1=Ready (LSE oscillator ready)
  [0] LSEON — LSE oscillator enabled
    0=Off (LSE oscillator Off); 1=On (LSE oscillator On)
0xF4 RSR reset 0xC000000 — RCC reset status register
  [31] LPWRRSTF — Low-power reset flag
    on read: 0=No reset occurred for block; 1=Reset occurred for block
  [30] WWDGRSTF — window watchdog reset flag
    values as LPWRRSTF
  [29] IWDGRSTF — independent watchdog reset flag
    values as LPWRRSTF
  [28] SFTRSTF — system reset from CPU reset flag
    values as LPWRRSTF
  [27] BORRSTF — BOR reset flag
    values as LPWRRSTF
  [26] PINRSTF — pin reset flag (NRST)
    values as LPWRRSTF
  [23] RMVF — remove reset flag
    0=NotActivated (Reset not activated); 1=Reset the reset status flags
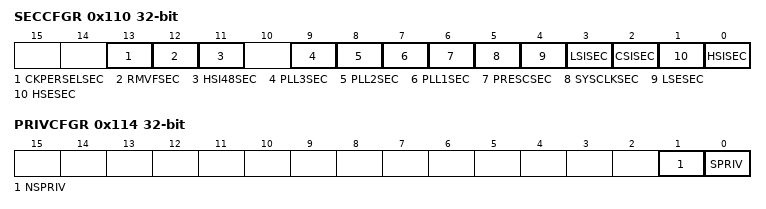
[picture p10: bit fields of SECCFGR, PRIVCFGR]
0x110 SECCFGR — RCC secure configuration register
  [all] fields
    0=NonSecure; 1=Secure
  [13] CKPERSELSEC — per_ck selection security
  [12] RMVFSEC — Remove reset flag security
  [11] HSI48SEC — HSI48 clock configuration and status bits security
  [9] PLL3SEC — PLL3 clock configuration and status bits security
  [8] PLL2SEC — PLL2 clock configuration and status bits security
  [7] PLL1SEC — PLL1 clock configuration and status bits security
  [6] PRESCSEC — AHBx/APBx prescaler configuration bits security
  [5] SYSCLKSEC — SYSCLK clock selection, STOPWUCK bit, clock output on MCO configuration security
  [4] LSESEC — LSE clock configuration and status bits security
  [3] LSISEC — LSI clock configuration and status bits security
  [2] CSISEC — CSI clock configuration and status bits security
  [1] HSESEC — HSE clock configuration bits, status bits and HSE_CSS security
  [0] HSISEC — HSI clock configuration and status bits security
0x114 PRIVCFGR — RCC privilege configuration register
  [1] NSPRIV — RCC non-secure functions privilege configuration
    0=Any (RCC functions can be modified by privileged or unprivileged access); 1=PrivilegedOnly (RCC functions can only be modified by privileged access)
  [0] SPRIV — RCC secure functions privilege configuration
    values as NSPRIV
